AUTOSAR XML (schema 4-0-3)
package /ComponentTypes
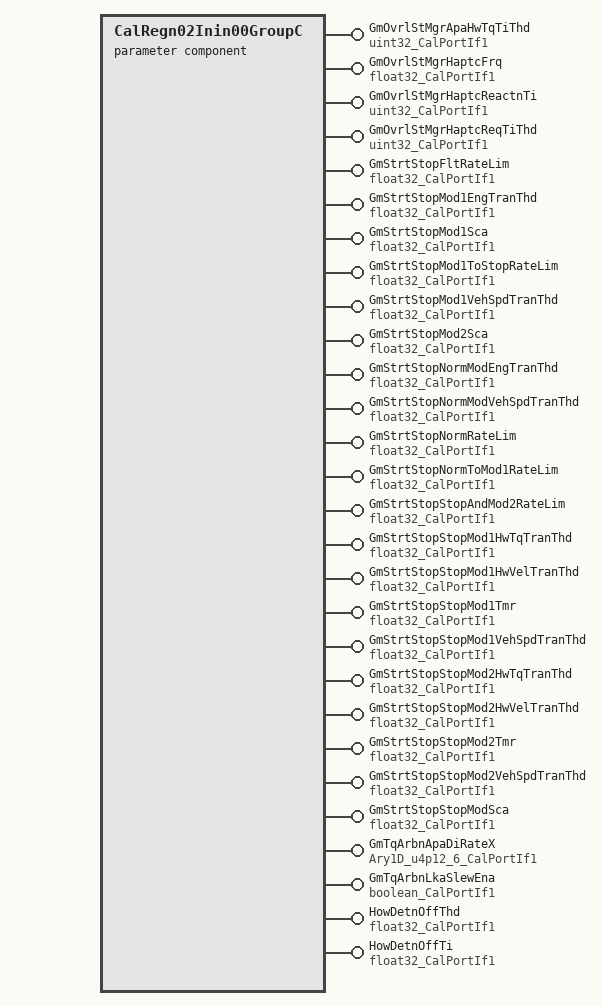
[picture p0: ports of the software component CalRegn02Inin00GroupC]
  parameter sw component type CalRegn02Inin00GroupC
    28 x provide port:
      GmOvrlStMgrApaHwTqTiThd: parameter-provide-com-spec{init-value=50, parameter=Val}, provided-interface=uint32_CalPortIf1
      GmOvrlStMgrHaptcFrq: parameter-provide-com-spec{init-value=10, parameter=Val}, provided-interface=float32_CalPortIf1
      GmOvrlStMgrHaptcReactnTi: parameter-provide-com-spec{init-value=350, parameter=Val}, provided-interface=uint32_CalPortIf1
      GmOvrlStMgrHaptcReqTiThd: parameter-provide-com-spec{init-value=500, parameter=Val}, provided-interface=uint32_CalPortIf1
      GmStrtStopFltRateLim: parameter-provide-com-spec{init-value=2, parameter=Val}, provided-interface=float32_CalPortIf1
      GmStrtStopMod1EngTranThd: parameter-provide-com-spec{init-value=3000, parameter=Val}, provided-interface=float32_CalPortIf1
      GmStrtStopMod1Sca: parameter-provide-com-spec{init-value=0.5, parameter=Val}, provided-interface=float32_CalPortIf1
      GmStrtStopMod1ToStopRateLim: parameter-provide-com-spec{init-value=0.8, parameter=Val}, provided-interface=float32_CalPortIf1
      GmStrtStopMod1VehSpdTranThd: parameter-provide-com-spec{init-value=10, parameter=Val}, provided-interface=float32_CalPortIf1
      GmStrtStopMod2Sca: parameter-provide-com-spec{init-value=0.5, parameter=Val}, provided-interface=float32_CalPortIf1
      GmStrtStopNormModEngTranThd: parameter-provide-com-spec{init-value=3000, parameter=Val}, provided-interface=float32_CalPortIf1
      GmStrtStopNormModVehSpdTranThd: parameter-provide-com-spec{init-value=12, parameter=Val}, provided-interface=float32_CalPortIf1
      GmStrtStopNormRateLim: parameter-provide-com-spec{init-value=0.4, parameter=Val}, provided-interface=float32_CalPortIf1
      GmStrtStopNormToMod1RateLim: parameter-provide-com-spec{init-value=1.5, parameter=Val}, provided-interface=float32_CalPortIf1
      GmStrtStopStopAndMod2RateLim: parameter-provide-com-spec{init-value=0.5, parameter=Val}, provided-interface=float32_CalPortIf1
      GmStrtStopStopMod1HwTqTranThd: parameter-provide-com-spec{init-value=1, parameter=Val}, provided-interface=float32_CalPortIf1
      GmStrtStopStopMod1HwVelTranThd: parameter-provide-com-spec{init-value=10, parameter=Val}, provided-interface=float32_CalPortIf1
      GmStrtStopStopMod1Tmr: parameter-provide-com-spec{init-value=100, parameter=Val}, provided-interface=float32_CalPortIf1
      GmStrtStopStopMod1VehSpdTranThd: parameter-provide-com-spec{init-value=5, parameter=Val}, provided-interface=float32_CalPortIf1
      GmStrtStopStopMod2HwTqTranThd: parameter-provide-com-spec{init-value=1, parameter=Val}, provided-interface=float32_CalPortIf1
      GmStrtStopStopMod2HwVelTranThd: parameter-provide-com-spec{init-value=10, parameter=Val}, provided-interface=float32_CalPortIf1
      GmStrtStopStopMod2Tmr: parameter-provide-com-spec{init-value=100, parameter=Val}, provided-interface=float32_CalPortIf1
      GmStrtStopStopMod2VehSpdTranThd: parameter-provide-com-spec{init-value=8, parameter=Val}, provided-interface=float32_CalPortIf1
      GmStrtStopStopModSca: parameter-provide-com-spec{init-value=0.001, parameter=Val}, provided-interface=float32_CalPortIf1
      GmTqArbnApaDiRateX: parameter-provide-com-spec{init-value=[0, 4096, 8192, 12288, 16384, 28672], parameter=Ary1D}, provided-interface=Ary1D_u4p12_6_CalPortIf1
      GmTqArbnLkaSlewEna: parameter-provide-com-spec{init-value=0, parameter=Logl}, provided-interface=boolean_CalPortIf1
      HowDetnOffThd: parameter-provide-com-spec{init-value=0.01, parameter=Val}, provided-interface=float32_CalPortIf1
      HowDetnOffTi: parameter-provide-com-spec{init-value=0, parameter=Val}, provided-interface=float32_CalPortIf1
